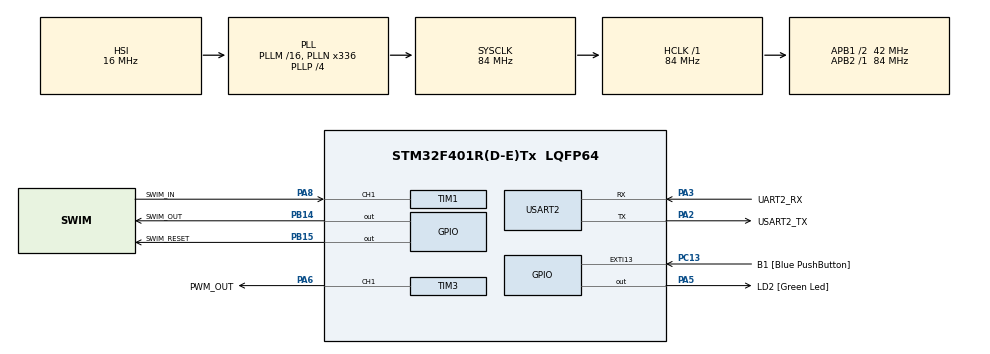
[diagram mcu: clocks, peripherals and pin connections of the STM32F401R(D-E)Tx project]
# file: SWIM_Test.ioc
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Dma.Request0=USART2_RX
Dma.Request1=TIM1_CH2
Dma.TIM1_CH2.1.Direction=DMA_PERIPH_TO_MEMORY
Dma.TIM1_CH2.1.FIFOMode=DMA_FIFOMODE_DISABLE
Dma.TIM1_CH2.1.Instance=DMA2_Stream2
Dma.TIM1_CH2.1.MemDataAlignment=DMA_MDATAALIGN_HALFWORD
Dma.TIM1_CH2.1.MemInc=DMA_MINC_ENABLE
Dma.TIM1_CH2.1.Mode=DMA_CIRCULAR
Dma.TIM1_CH2.1.PeriphDataAlignment=DMA_PDATAALIGN_HALFWORD
Dma.TIM1_CH2.1.PeriphInc=DMA_PINC_DISABLE
Dma.TIM1_CH2.1.Priority=DMA_PRIORITY_LOW
Dma.USART2_RX.0.Direction=DMA_PERIPH_TO_MEMORY
Dma.USART2_RX.0.FIFOMode=DMA_FIFOMODE_DISABLE
Dma.USART2_RX.0.Instance=DMA1_Stream5
Dma.USART2_RX.0.MemDataAlignment=DMA_MDATAALIGN_BYTE
Dma.USART2_RX.0.MemInc=DMA_MINC_ENABLE
Dma.USART2_RX.0.Mode=DMA_NORMAL
Dma.USART2_RX.0.PeriphDataAlignment=DMA_PDATAALIGN_BYTE
Dma.USART2_RX.0.PeriphInc=DMA_PINC_DISABLE
Dma.USART2_RX.0.Priority=DMA_PRIORITY_VERY_HIGH
FREERTOS.Tasks01=IdleTask,24,128,StartIdleTask,Default,NULL,Dynamic,NULL,NULL
FREERTOS.configUSE_NEWLIB_REENTRANT=1
Mcu.Family=STM32F4
Mcu.Name=STM32F401R(D-E)Tx
Mcu.Package=LQFP64
NVIC.DMA1_Stream5_IRQn=true\:5\:0\:false\:false\:true\:true\:false\:true\:true
NVIC.DMA2_Stream2_IRQn=true\:5\:0\:false\:false\:true\:false\:true\:true\:true
NVIC.PriorityGroup=NVIC_PRIORITYGROUP_4
NVIC.TIM1_CC_IRQn=true\:5\:0\:false\:false\:true\:true\:true\:true\:true
NVIC.TIM2_IRQn=true\:15\:0\:false\:false\:true\:false\:false\:true\:true
NVIC.TimeBase=TIM2_IRQn
NVIC.TimeBaseIP=TIM2
NVIC.USART2_IRQn=true\:5\:0\:false\:false\:true\:true\:true\:true\:true
PA13.GPIO_Label=TMS
PA13.Mode=Serial_Wire
PA13.Signal=SYS_JTMS-SWDIO
PA14.GPIO_Label=TCK
PA14.Mode=Serial_Wire
PA14.Signal=SYS_JTCK-SWCLK
PA2.GPIO_Label=USART2_TX
PA2.GPIO_Mode=GPIO_MODE_AF_PP
PA2.GPIO_PuPd=GPIO_NOPULL
PA2.GPIO_Speed=GPIO_SPEED_FREQ_LOW
PA2.Mode=Asynchronous
PA2.Signal=USART2_TX
PA3.GPIO_Label=UART2_RX
PA3.Mode=Asynchronous
PA3.Signal=USART2_RX
PA5.GPIO_Label=LD2 [Green Led]
PA5.GPIO_Mode=GPIO_MODE_OUTPUT_PP
PA5.GPIO_PuPd=GPIO_NOPULL
PA5.GPIO_Speed=GPIO_SPEED_FREQ_LOW
PA5.Signal=GPIO_Output
PA6.GPIO_Label=PWM_OUT
PA6.Signal=S_TIM3_CH1
PA8.GPIO_Label=SWIM_IN
PA8.Signal=S_TIM1_CH1
PB14.GPIO_Label=SWIM_OUT
PB14.GPIO_Speed=GPIO_SPEED_FREQ_VERY_HIGH
PB14.Signal=GPIO_Output
PB15.GPIO_Label=SWIM_RESET
PB15.Signal=GPIO_Output
PB3.GPIO_Label=SWO
PB3.Signal=SYS_JTDO-SWO
PC13-ANTI_TAMP.GPIO_Label=B1 [Blue PushButton]
PC13-ANTI_TAMP.GPIO_ModeDefaultEXTI=GPIO_MODE_IT_FALLING
PC13-ANTI_TAMP.GPIO_PuPd=GPIO_NOPULL
PC13-ANTI_TAMP.Signal=GPXTI13
PC14-OSC32_IN.Signal=RCC_OSC32_IN
PC15-OSC32_OUT.Signal=RCC_OSC32_OUT
PH0\ -\ OSC_IN.Signal=RCC_OSC_IN
PH1\ -\ OSC_OUT.Signal=RCC_OSC_OUT
ProjectManager.HeapSize=0x200
ProjectManager.StackSize=0x400
ProjectManager.TargetToolchain=STM32CubeIDE
RCC.AHBFreq_Value=84000000
RCC.APB1CLKDivider=RCC_HCLK_DIV2
RCC.APB1Freq_Value=42000000
RCC.APB1TimFreq_Value=84000000
RCC.APB2Freq_Value=84000000
RCC.APB2TimFreq_Value=84000000
RCC.CortexFreq_Value=84000000
RCC.HCLKFreq_Value=84000000
RCC.HSE_VALUE=8000000
RCC.HSI_VALUE=16000000
RCC.LSE_VALUE=32768
RCC.PLLN=336
RCC.PLLP=RCC_PLLP_DIV4
RCC.PLLQ=7
RCC.SYSCLKFreq_VALUE=84000000
RCC.SYSCLKSource=RCC_SYSCLKSOURCE_PLLCLK
RCC.VCOOutputFreq_Value=336000000
SH.S_TIM1_CH1.0=TIM1_CH1,TriggerSource_TI1FP1
SH.S_TIM1_CH1.1=TIM1_CH1,Input_Capture1_from_TI1
SH.S_TIM3_CH1.0=TIM3_CH1,PWM Generation1 CH1
TIM1.Channel-Input_Capture1_from_TI1=TIM_CHANNEL_1
TIM1.Channel-Input_Capture2_from_TI1_63=TIM_CHANNEL_2
TIM1.ICPolarity_CH1=TIM_INPUTCHANNELPOLARITY_FALLING
TIM3.Channel-PWM\ Generation1\ CH1=TIM_CHANNEL_1
TIM3.OC1Preload_PWM=DISABLE
TIM3.Period=0
TIM3.Prescaler=0
TIM3.Pulse-PWM\ Generation1\ CH1=500
TIM3.TIM_MasterOutputTrigger=TIM_TRGO_UPDATE
USART2.VirtualMode=VM_ASYNC
VP_FREERTOS_VS_CMSIS_V2.Mode=CMSIS_V2
VP_SYS_VS_tim2.Mode=TIM2
VP_TIM1_VS_ClockSourceINT.Mode=Internal
VP_TIM1_VS_ControllerModeReset.Mode=Reset Mode
VP_TIM1_VS_indirect_ch1.Mode=Input_Capture2_from_TI1_63
VP_TIM3_VS_ClockSourceINT.Mode=Internal
board=NUCLEO-F401RE

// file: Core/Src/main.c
/* USER CODE BEGIN Header */
/**
  ******************************************************************************
  * @file           : main.c
  * @brief          : Main program body
  ******************************************************************************
  * @attention
  *
  * Copyright (c) 2023 STMicroelectronics.
  * All rights reserved.
  *
  * This software is licensed under terms that can be found in the LICENSE file
  * in the root directory of this software component.
  * If no LICENSE file comes with this software, it is provided AS-IS.
  *
  ******************************************************************************
  */
/* USER CODE END Header */
#include "main.h"
#include "cmsis_os.h"
#include "dma.h"
#include "tim.h"
#include "usart.h"
#include "gpio.h"

void SystemClock_Config(void);
void MX_FREERTOS_Init(void);

/* USER CODE BEGIN 0 */
uint16_t capture1[2];
uint16_t capture2[2];
/* USER CODE END 0 */

int main(void)
{

  /* MCU Configuration--------------------------------------------------------*/

  /* Reset of all peripherals, Initializes the Flash interface and the Systick. */
  HAL_Init();

  /* Configure the system clock */
  SystemClock_Config();

  /* Initialize all configured peripherals */
  MX_GPIO_Init();
  MX_DMA_Init();
  MX_USART2_UART_Init();
  MX_TIM1_Init();
  MX_TIM3_Init();
  /* USER CODE BEGIN 2 */
//  HAL_TIM_IC_Start_DMA(&htim1, TIM_CHANNEL_1, (uint32_t *)capture1, 2);
//  htim1.State = HAL_TIM_STATE_READY;
//  HAL_TIM_IC_Start_DMA(&htim1, TIM_CHANNEL_2, (uint32_t *)capture1, 2);

  HAL_TIM_PWM_Start(&htim3, TIM_CHANNEL_1);
  /* USER CODE END 2 */

  /* Init scheduler */
  osKernelInitialize();  /* Call init function for freertos objects (in freertos.c) */
  MX_FREERTOS_Init();

  /* Start scheduler */
  osKernelStart();

  /* We should never get here as control is now taken by the scheduler */
  /* Infinite loop */
  while (1)
  {

  }
}

void SystemClock_Config(void)
{
  RCC_OscInitTypeDef RCC_OscInitStruct = {0};
  RCC_ClkInitTypeDef RCC_ClkInitStruct = {0};

  /** Configure the main internal regulator output voltage
  */
  __HAL_RCC_PWR_CLK_ENABLE();
  __HAL_PWR_VOLTAGESCALING_CONFIG(PWR_REGULATOR_VOLTAGE_SCALE2);

  /** Initializes the RCC Oscillators according to the specified parameters
  * in the RCC_OscInitTypeDef structure.
  */
  RCC_OscInitStruct.OscillatorType = RCC_OSCILLATORTYPE_HSI;
  RCC_OscInitStruct.HSIState = RCC_HSI_ON;
  RCC_OscInitStruct.HSICalibrationValue = RCC_HSICALIBRATION_DEFAULT;
  RCC_OscInitStruct.PLL.PLLState = RCC_PLL_ON;
  RCC_OscInitStruct.PLL.PLLSource = RCC_PLLSOURCE_HSI;
  RCC_OscInitStruct.PLL.PLLM = 16;
  RCC_OscInitStruct.PLL.PLLN = 336;
  RCC_OscInitStruct.PLL.PLLP = RCC_PLLP_DIV4;
  RCC_OscInitStruct.PLL.PLLQ = 7;
  if (HAL_RCC_OscConfig(&RCC_OscInitStruct) != HAL_OK)
  {
    Error_Handler();
  }

  /** Initializes the CPU, AHB and APB buses clocks
  */
  RCC_ClkInitStruct.ClockType = RCC_CLOCKTYPE_HCLK|RCC_CLOCKTYPE_SYSCLK
                              |RCC_CLOCKTYPE_PCLK1|RCC_CLOCKTYPE_PCLK2;
  RCC_ClkInitStruct.SYSCLKSource = RCC_SYSCLKSOURCE_PLLCLK;
  RCC_ClkInitStruct.AHBCLKDivider = RCC_SYSCLK_DIV1;
  RCC_ClkInitStruct.APB1CLKDivider = RCC_HCLK_DIV2;
  RCC_ClkInitStruct.APB2CLKDivider = RCC_HCLK_DIV1;

  if (HAL_RCC_ClockConfig(&RCC_ClkInitStruct, FLASH_LATENCY_2) != HAL_OK)
  {
    Error_Handler();
  }
}

void HAL_TIM_PeriodElapsedCallback(TIM_HandleTypeDef *htim)
{
  if (htim->Instance == TIM2) {
    HAL_IncTick();
  }
}

void Error_Handler(void)
{
  __disable_irq();
  while (1)
  {
  }
}

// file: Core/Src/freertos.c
/* USER CODE BEGIN Header */
/**
  ******************************************************************************
  * File Name          : freertos.c
  * Description        : Code for freertos applications
  ******************************************************************************
  * @attention
  *
  * Copyright (c) 2023 STMicroelectronics.
  * All rights reserved.
  *
  * This software is licensed under terms that can be found in the LICENSE file
  * in the root directory of this software component.
  * If no LICENSE file comes with this software, it is provided AS-IS.
  *
  ******************************************************************************
  */
/* USER CODE END Header */

#include "FreeRTOS.h"
#include "task.h"
#include "main.h"
#include "cmsis_os.h"

/* USER CODE BEGIN Includes */
#include "ConsoleTask.h"

/* USER CODE END Includes */

/* Definitions for IdleTask */
osThreadId_t IdleTaskHandle;
const osThreadAttr_t IdleTask_attributes = {
  .name = "IdleTask",
  .stack_size = 128 * 4,
  .priority = (osPriority_t) osPriorityNormal,
};

void StartIdleTask(void *argument);

void MX_FREERTOS_Init(void); /* (MISRA C 2004 rule 8.1) */

void MX_FREERTOS_Init(void) {
  /* USER CODE BEGIN Init */
	IdleTaskHandle = osThreadNew(StartIdleTask, NULL, &IdleTask_attributes);

	CreateConsoleTask();

  /* USER CODE END Init */
/* USER CODE BEGIN Header */
/**
  ******************************************************************************
  * File Name          : freertos.c
  * Description        : Code for freertos applications
  ******************************************************************************
  * @attention
  *
  * Copyright (c) 2023 STMicroelectronics.
  * All rights reserved.
  *
  * This software is licensed under terms that can be found in the LICENSE file
  * in the root directory of this software component.
  * If no LICENSE file comes with this software, it is provided AS-IS.
  *
  ******************************************************************************
  */
/* USER CODE END Header */

}

void StartIdleTask(void *argument)
{
  for(;;)
  {
    osDelay(1);
  }
}
